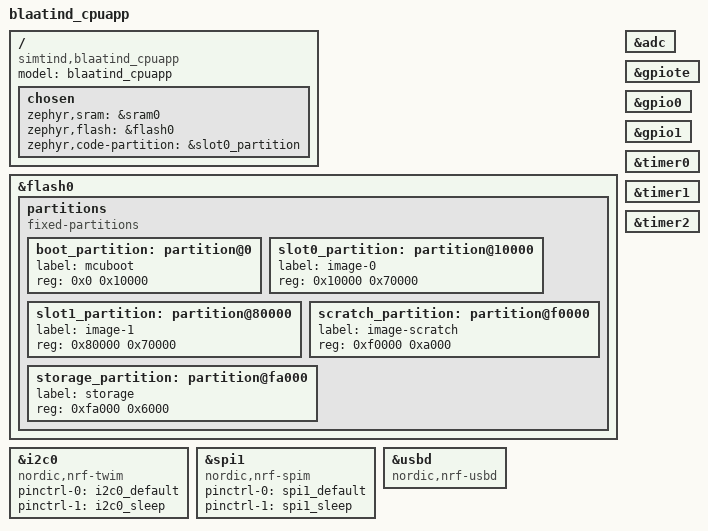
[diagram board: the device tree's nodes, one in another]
// Copyright (c) 2022 Nordic Semiconductor ASA
// SPDX-License-Identifier: Apache-2.0

/dts-v1/;
#include <nordic/nrf5340_cpuapp_qkaa.dtsi>
#include "blaatind_cpuapp-pinctrl.dtsi"

/ {
	model = "blaatind_cpuapp";
	compatible = "simtind,blaatind_cpuapp";

	chosen {
		zephyr,sram = &sram0;
		zephyr,flash = &flash0;
		zephyr,code-partition = &slot0_partition;
	};
};

&flash0 {
	partitions {
		compatible = "fixed-partitions";
		#address-cells = <1>;
		#size-cells = <1>;

		boot_partition: partition@0 {
			label = "mcuboot";
			reg = <0x0 0x10000>;
		};
		slot0_partition: partition@10000 {
			label = "image-0";
			reg = <0x10000 0x70000>;
		};
		slot1_partition: partition@80000 {
			label = "image-1";
			reg = <0x80000 0x70000>;
		};
		scratch_partition: partition@f0000 {
			label = "image-scratch";
			reg = <0xf0000 0xa000>;
		};
		storage_partition: partition@fa000 {
			label = "storage";
			reg = <0xfa000 0x6000>;
		};
	};
};

&adc {
	status = "okay";
};

&gpiote {
	status = "okay";
};

&gpio0 {
	status = "okay";
};

&gpio1 {
	status = "okay";
};

&timer0 {
	status = "okay";
};

&timer1 {
	status = "okay";
};

&timer2 {
	status = "okay";
};

&i2c0 {
	compatible = "nordic,nrf-twim";
	status = "okay";
	pinctrl-0 = <&i2c0_default>;
	pinctrl-1 = <&i2c0_sleep>;
	pinctrl-names = "default", "sleep";
};

&spi1 {
	compatible = "nordic,nrf-spim";
	status = "okay";
	pinctrl-0 = <&spi1_default>;
	pinctrl-1 = <&spi1_sleep>;
	pinctrl-names = "default", "sleep";
};

zephyr_udc0: &usbd {
	compatible = "nordic,nrf-usbd";
	status = "okay";
};

#include "blaatind_shared_sram_planning_conf.dts"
